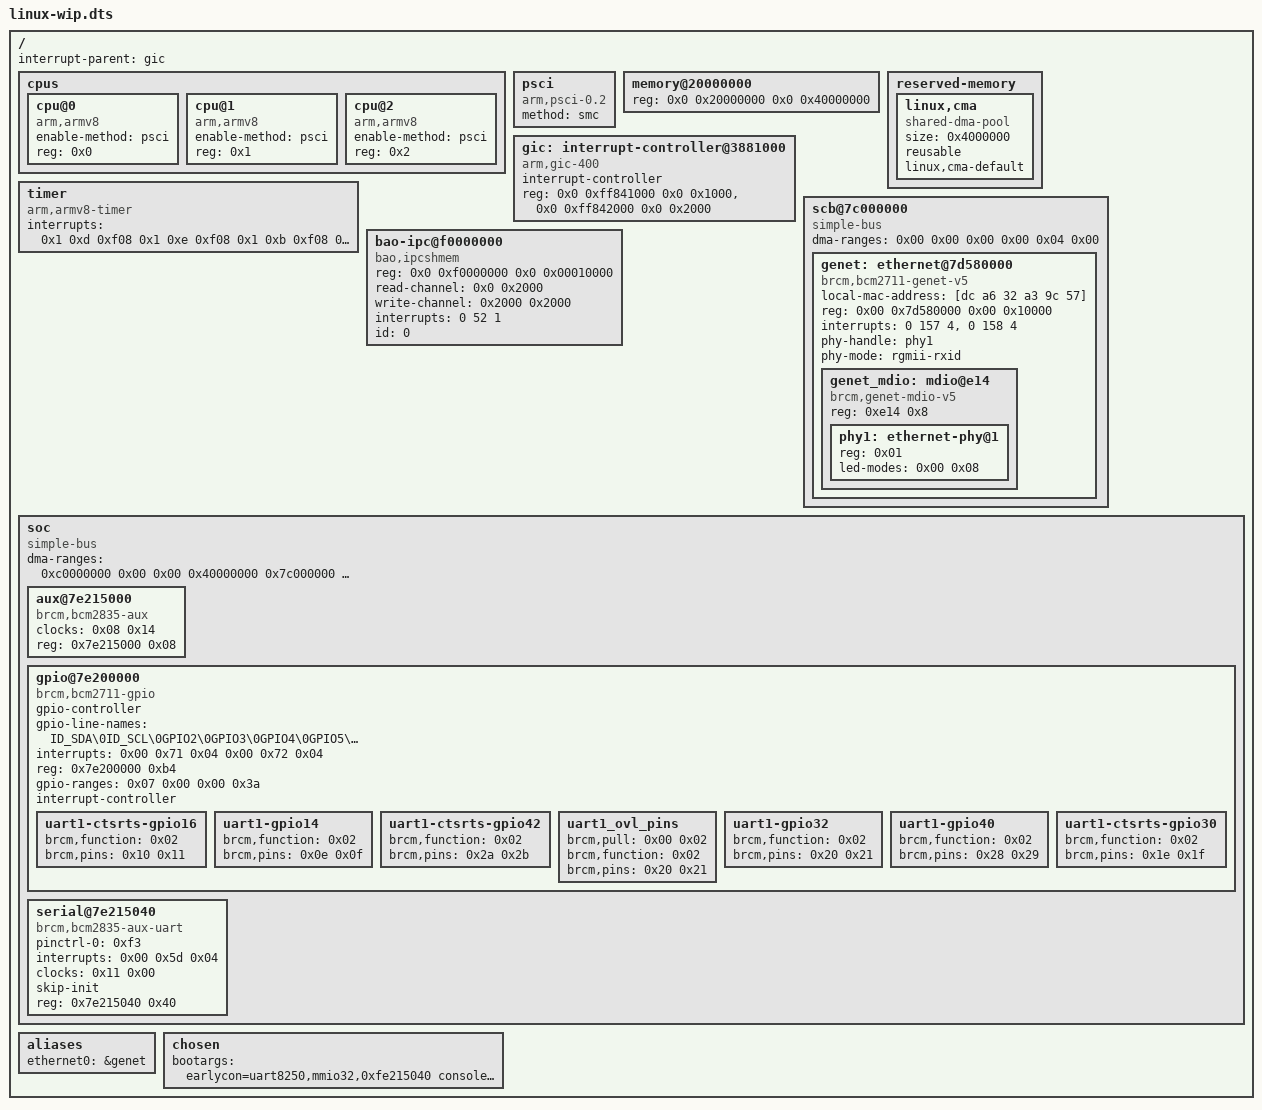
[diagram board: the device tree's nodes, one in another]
/dts-v1/;

/ {
	#address-cells = <2>;
	#size-cells = <2>;
	interrupt-parent = <&gic>;

	cpus {
		#size-cells = <0x0>;
		#address-cells = <0x1>;

		cpu@0 {
			compatible = "arm,armv8";
			device_type = "cpu";
			enable-method = "psci";
			reg = <0x0>;
		};

		cpu@1 {
			compatible = "arm,armv8";
			device_type = "cpu";
			enable-method = "psci";
			reg = <0x1>;
		};

		cpu@2 {
			compatible = "arm,armv8";
			device_type = "cpu";
			enable-method = "psci";
			reg = <0x2>;
		};

	};

	psci {
		compatible = "arm,psci-0.2";
		method = "smc";
	};

	memory@20000000 {
		reg = <0x0 0x20000000 0x0 0x40000000>;
		device_type = "memory";
	};

	reserved-memory {
		#address-cells = <0x02>;
		#size-cells = <0x01>;
		ranges;

		linux,cma {
			compatible = "shared-dma-pool";
			size = <0x4000000>;
			reusable;
			linux,cma-default;
		};
	};

	gic: interrupt-controller@3881000 {
		compatible = "arm,gic-400";
		#interrupt-cells = <3>;
		interrupt-controller;
		reg = <0x0 0xff841000 0x0 0x1000>,
		      <0x0 0xff842000 0x0 0x2000>;
	};

	timer {
		compatible = "arm,armv8-timer";
		interrupts = <0x1 0xd 0xf08 0x1 0xe 0xf08 0x1 0xb 0xf08 0x1 0xa 0xf08>;
	};

	scb@7c000000 {
		compatible = "simple-bus";
		#address-cells = <0x02>;
		#size-cells = < 0x02 >;
		dma-ranges = < 0x00 0x00 0x00 0x00 0x04 0x00 >;
		ranges = < 0x00 0x7c000000 0x00 0xfc000000 0x00 0x3800000 0x00 0x40000000 0x00 0xff800000 0x00 0x800000 0x06 0x00 0x06 0x00 0x00 0x40000000 0x00 0x00 0x00 0x00 0x00 0xfc000000 >;

		genet: ethernet@7d580000 {
			local-mac-address = [dc a6 32 a3 9c 57];
			compatible = "brcm,bcm2711-genet-v5", "brcm,genet-v5";
			reg = < 0x00 0x7d580000 0x00 0x10000 >;
			#address-cells = <0x1>;
			#size-cells = <0x1>;
			interrupts = <0 157 4>,
						<0 158 4>;
			status = "okay";

			phy-handle = <&phy1>;
			phy-mode = "rgmii-rxid";

			genet_mdio: mdio@e14 {
				compatible = "brcm,genet-mdio-v5";
				reg = <0xe14 0x8>;
				reg-names = "mdio";
				#address-cells = <0x0>;
				#size-cells = <0x1>;

				phy1: ethernet-phy@1 {
					reg = <0x01>;
					led-modes = < 0x00 0x08 >;
				};
			};
		};
	};

    bao-ipc@f0000000 {
        compatible = "bao,ipcshmem";
        reg = <0x0 0xf0000000 0x0 0x00010000>;
		read-channel = <0x0 0x2000>;
		write-channel = <0x2000 0x2000>;
        interrupts = <0 52 1>;
		id = <0>;
    };


	soc {
		compatible = "simple-bus";
		#address-cells = <0x01>;
		#size-cells = <0x01>;
		ranges = <0x7e000000 0x00 0xfe000000 0x1800000 0x7c000000 0x00 0xfc000000 0x2000000 0x40000000 0x00 0xff800000 0x800000>;
		dma-ranges = <0xc0000000 0x00 0x00 0x40000000 0x7c000000 0x00 0xfc000000 0x3800000>;
		phandle = <0x5f>;


		aux@7e215000 {
			clocks = <0x08 0x14>;
			#clock-cells = <0x01>;
			compatible = "brcm,bcm2835-aux";
			reg = <0x7e215000 0x08>;
			phandle = <0x11>;
		};


		gpio@7e200000 {
			gpio-controller;
			gpio-line-names = "ID_SDA\0ID_SCL\0GPIO2\0GPIO3\0GPIO4\0GPIO5\0GPIO6\0GPIO7\0GPIO8\0GPIO9\0GPIO10\0GPIO11\0GPIO12\0GPIO13\0GPIO14\0GPIO15\0GPIO16\0GPIO17\0GPIO18\0GPIO19\0GPIO20\0GPIO21\0GPIO22\0GPIO23\0GPIO24\0GPIO25\0GPIO26\0GPIO27\0RGMII_MDIO\0RGMIO_MDC\0CTS0\0RTS0\0TXD0\0RXD0\0SD1_CLK\0SD1_CMD\0SD1_DATA0\0SD1_DATA1\0SD1_DATA2\0SD1_DATA3\0PWM0_MISO\0PWM1_MOSI\0STATUS_LED_G_CLK\0SPIFLASH_CE_N\0SDA0\0SCL0\0RGMII_RXCLK\0RGMII_RXCTL\0RGMII_RXD0\0RGMII_RXD1\0RGMII_RXD2\0RGMII_RXD3\0RGMII_TXCLK\0RGMII_TXCTL\0RGMII_TXD0\0RGMII_TXD1\0RGMII_TXD2\0RGMII_TXD3";
			interrupts = <0x00 0x71 0x04 0x00 0x72 0x04>;
			compatible = "brcm,bcm2711-gpio";
			#interrupt-cells = <0x02>;
			reg = <0x7e200000 0xb4>;
			phandle = <0x07>;
			#gpio-cells = <0x02>;
			gpio-ranges = <0x07 0x00 0x00 0x3a>;
			interrupt-controller;


			uart1-ctsrts-gpio16 {
				brcm,function = <0x02>;
				phandle = <0x7f>;
				brcm,pins = <0x10 0x11>;
			};

			uart1-gpio14 {
				brcm,function = <0x02>;
				phandle = <0x7e>;
				brcm,pins = <0x0e 0x0f>;
			};

			uart1-ctsrts-gpio42 {
				brcm,function = <0x02>;
				phandle = <0x83>;
				brcm,pins = <0x2a 0x2b>;
			};

			uart1_ovl_pins {
				brcm,pull = <0x00 0x02>;
				brcm,function = <0x02>;
				phandle = <0xf3>;
				brcm,pins = <0x20 0x21>;
			};

			uart1-gpio32 {
				brcm,function = <0x02>;
				phandle = <0x80>;
				brcm,pins = <0x20 0x21>;
			};

			uart1-gpio40 {
				brcm,function = <0x02>;
				phandle = <0x82>;
				brcm,pins = <0x28 0x29>;
			};

			uart1-ctsrts-gpio30 {
				brcm,function = <0x02>;
				phandle = <0x81>;
				brcm,pins = <0x1e 0x1f>;
			};
		}

		serial@7e215040 {
			pinctrl-names = "default";
			pinctrl-0 = <0xf3>;
			interrupts = <0x00 0x5d 0x04>;
			clocks = <0x11 0x00>;
			skip-init;
			compatible = "brcm,bcm2835-aux-uart";
			status = "okay";
			reg = <0x7e215040 0x40>;
			phandle = <0x44>;
		};

	}

	aliases {
		ethernet0 = &genet;
	};

	chosen {
		bootargs = "earlycon=uart8250,mmio32,0xfe215040 console=serial0,115200 console=tty1 clk_ignore_unused ip=192.168.42.15 carrier_timeout=0";
	};

};
